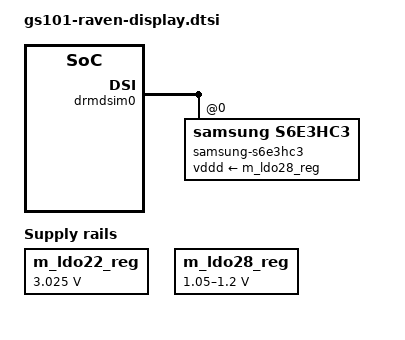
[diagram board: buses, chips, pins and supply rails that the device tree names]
// SPDX-License-Identifier: GPL-2.0-only
/*
 * Google GS101 Raven-specific display device tree source
 *
 * Copyright (c) 2020 Google, LLC
 *
 */

&drmdsim0 {
	samsung_s6e3hc3: panel@0 {
		compatible = "samsung,s6e3hc3";
		label = "samsung-s6e3hc3";
		channel = <0>;
		touch = <&spitouch>;

		vddd-supply = <&m_ldo28_reg>;
		vddd-normal-microvolt = <1200000>;
		vddd-lp-microvolt     = <1050000>;
		/* vddi is from PP1850_SA which is always on */
		/delete-node/ vddi-supply;
	};
};

/* vci-supply voltage */
&m_ldo22_reg {
	regulator-min-microvolt = <3025000>;
	regulator-max-microvolt = <3025000>;
};

/* vddd-supply voltage */
&m_ldo28_reg {
	regulator-min-microvolt = <1050000>;
	regulator-max-microvolt = <1200000>;
	regulator-ramp-delay = <1200>;
	regulator-enable-ramp-delay = <125>;
};

